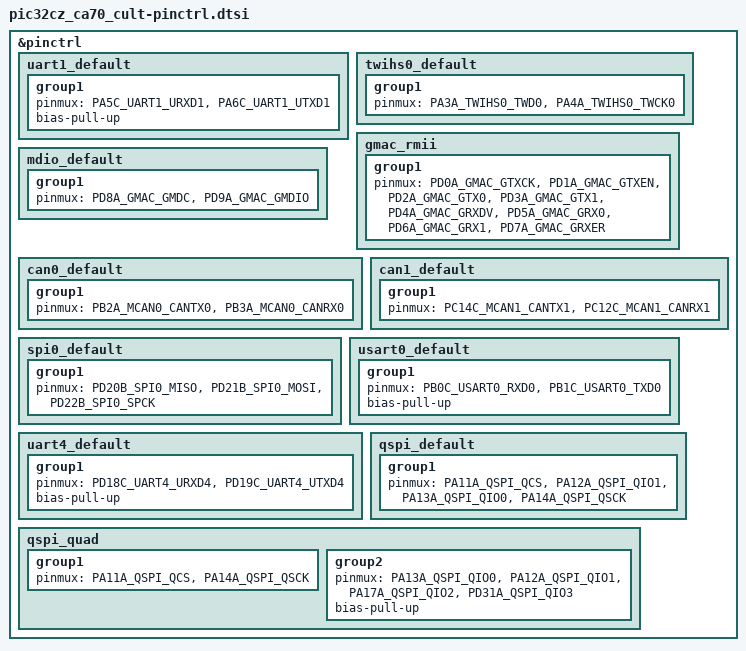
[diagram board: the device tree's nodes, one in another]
/*
 * SPDX-FileCopyrightText: Copyright The Zephyr Project Contributors
 *
 * SPDX-License-Identifier: Apache-2.0
 */

&pinctrl {
	/* UART1 to the on-board debugger virtual COM port */
	uart1_default: uart1_default {
		group1 {
			pinmux = <PA5C_UART1_URXD1>,
				 <PA6C_UART1_UTXD1>;
			bias-pull-up;
		};
	};

	/* TWIHS0 to the AT24MAC402 EEPROM and the extension headers */
	twihs0_default: twihs0_default {
		group1 {
			pinmux = <PA3A_TWIHS0_TWD0>,
				 <PA4A_TWIHS0_TWCK0>;
		};
	};

	/* GMAC RMII to the PHY daughter board header J700/J701 */
	gmac_rmii: gmac_rmii {
		group1 {
			pinmux = <PD0A_GMAC_GTXCK>,
				 <PD1A_GMAC_GTXEN>,
				 <PD2A_GMAC_GTX0>,
				 <PD3A_GMAC_GTX1>,
				 <PD4A_GMAC_GRXDV>,
				 <PD5A_GMAC_GRX0>,
				 <PD6A_GMAC_GRX1>,
				 <PD7A_GMAC_GRXER>;
		};
	};

	mdio_default: mdio_default {
		group1 {
			pinmux = <PD8A_GMAC_GMDC>,
				 <PD9A_GMAC_GMDIO>;
		};
	};

	/* MCAN0 to the ATA6561 transceiver U700 */
	can0_default: can0_default {
		group1 {
			pinmux = <PB2A_MCAN0_CANTX0>,
				 <PB3A_MCAN0_CANRX0>;
		};
	};

	/* MCAN1 to the ATA6561 transceiver U701 */
	can1_default: can1_default {
		group1 {
			pinmux = <PC14C_MCAN1_CANTX1>,
				 <PC12C_MCAN1_CANRX1>;
		};
	};

	/* SPI0 to the Arduino (D11 MOSI, D12 MISO, D13 SCK) and mikroBUS headers */
	spi0_default: spi0_default {
		group1 {
			pinmux = <PD20B_SPI0_MISO>,
				 <PD21B_SPI0_MOSI>,
				 <PD22B_SPI0_SPCK>;
		};
	};

	/* USART0 on the mikroBUS socket J803 (pin 3 RX, pin 4 TX) */
	usart0_default: usart0_default {
		group1 {
			pinmux = <PB0C_USART0_RXD0>,
				 <PB1C_USART0_TXD0>;
			bias-pull-up;
		};
	};

	/* UART4 on J402 (pin 1 RX, pin 2 TX) */
	uart4_default: uart4_default {
		group1 {
			pinmux = <PD18C_UART4_URXD4>,
				 <PD19C_UART4_UTXD4>;
			bias-pull-up;
		};
	};

	/* QSPI in SPI mode; QIO2 (WP#) and QIO3 (HOLD#) are GPIOs of the flash node */
	qspi_default: qspi_default {
		group1 {
			pinmux = <PA11A_QSPI_QCS>,
				 <PA12A_QSPI_QIO1>,
				 <PA13A_QSPI_QIO0>,
				 <PA14A_QSPI_QSCK>;
		};
	};

	/*
	 * QSPI in serial memory mode, quad I/O. The pull-ups keep the data
	 * lines high while the controller does not drive them (dummy cycles).
	 */
	qspi_quad: qspi_quad {
		group1 {
			pinmux = <PA11A_QSPI_QCS>,
				 <PA14A_QSPI_QSCK>;
		};
		group2 {
			pinmux = <PA13A_QSPI_QIO0>,
				 <PA12A_QSPI_QIO1>,
				 <PA17A_QSPI_QIO2>,
				 <PD31A_QSPI_QIO3>;
			bias-pull-up;
		};
	};
};
